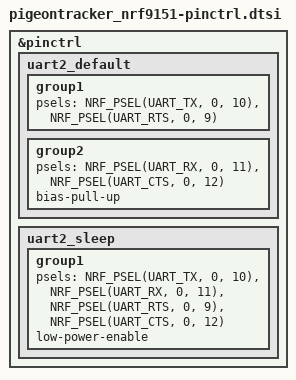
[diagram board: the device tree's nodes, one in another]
/*
 * PigeonTracker nRF9151 Pin Control Configuration
 *
 * Copyright (c) 2026 nRFModule
 * SPDX-License-Identifier: Apache-2.0
 *
 * Pin mapping for Serial Modem firmware (ncs-serial-modem).
 * Wiring is identical to LiveTracker; verified against the
 * nRF_tracker_pigeon v1.0 netlist (2026-07-30).
 */

&pinctrl {
	/*
	 * External MCU UART (nRF9151 <-> nRF52840), 921600 + HW flow control:
	 *   TX:  P0.10 -> nRF52840 P0.08 (RX)
	 *   RX:  P0.11 <- nRF52840 P0.06 (TX)
	 *   RTS: P0.09 -> nRF52840 P1.06 (CTS)
	 *   CTS: P0.12 <- nRF52840 P1.03 (RTS)
	 *
	 * RTS/CTS deliberately swapped vs the PCB net names: electrically
	 * correct pairing with the 52840's RTS P1.03 / CTS P1.06.
	 */
	uart2_default: uart2_default {
		group1 {
			psels = <NRF_PSEL(UART_TX, 0, 10)>,
				<NRF_PSEL(UART_RTS, 0, 9)>;
		};
		group2 {
			psels = <NRF_PSEL(UART_RX, 0, 11)>,
				<NRF_PSEL(UART_CTS, 0, 12)>;
			bias-pull-up;
		};
	};

	uart2_sleep: uart2_sleep {
		group1 {
			psels = <NRF_PSEL(UART_TX, 0, 10)>,
				<NRF_PSEL(UART_RX, 0, 11)>,
				<NRF_PSEL(UART_RTS, 0, 9)>,
				<NRF_PSEL(UART_CTS, 0, 12)>;
			low-power-enable;
		};
	};
};
